# ADUC7023 register map
File version: 1.0
Registers are 32-bit, read-write, reset 0x0 unless marked. A register's access mark holds for its fields unless they carry their own. Offsets are from the block's base; lines under a group give offsets from that group; [hi:lo] are bit positions; {n}, {i} and the like mark numbered series; 'fields as' and 'values as' point back to an identical list; <NAME> marks a mode.

## Memory map
0xFFFF0000 IRQ size 0x140 — NTERRUPT CONTROLLER
0xFFFF0220 RSC size 0x18 — REMAP AND SYSTEM CONTROL
0xFFFF0300 TIMER0 size 0x10
0xFFFF0320 GPT size 0x14 — GENERAL-PURPOSE TIMER
0xFFFF0360 WDT size 0x10 — WATCHDOG TIMER
0xFFFF0404 PLL size 0x1C — PLL AND OSCILLATOR CONTROL
0xFFFF0440 PSM size 0x8 — POWER SUPPLY MONITOR
0xFFFF048C REF size 0x4 — BAND GAP REFERENCE
0xFFFF0500 ADC size 0x5C — Analog-to-Digital Converter
0xFFFF0600 DAC size 0x6C — Digital-to-Analog Converter
0xFFFF0800 I2C0 size 0x48 — I2C0 peripheral interfaces
0xFFFF0900 I2C1 size 0x48 — I2C1 peripheral interfaces
0xFFFF0A00 SPI size 0x14 — SERIAL PERIPHERAL INTERFACE
0xFFFF0B00 PLA size 0x54 — PROGRAMMABLE LOGIC ARRAY
0xFFFF0F80 PWM size 0x3F — PROGRAMMABLE LOGIC ARRAY
0xFFFFF400 GPIO size 0x50 — GENERAL-PURPOSE INPUT/OUTPUT
0xFFFFF800 FLASH size 0x20 — FLASH/EE CONTROL INTERFACE

## IRQ — NTERRUPT CONTROLLER
Base 0xFFFF0000
0x00 IRQSTA ro — Active IRQ source register
0x04 IRQSIG ro — Current state of all IRQ sources register
0x08 IRQEN — Enabled IRQ sources register
0x0C IRQCLR wo — Register to disable IRQ sources
0x10 SWICFG wo — Software interrupt configuration register
0x14 IRQBASE — Base address of all vectors register
0x1C IRQVEC ro — Currently active IRQ source register
{0x20+4i} IRQP{i} (i=0..2) — Interrupt priority setting register
0x30 IRQCONN — IRQ and FIQ interrupt nesting register
0x34 IRQCONE — External interrupt sources register
0x38 IRQCLRE — Clear an edge level triggered interrupt source register
0x3C IRQSTAN — Register indicates the priority level of an interrupt
0x100 FIQSTA ro — Active FIQ source register
0x104 FIQSIG ro — Current state of all FIQ sources register
0x108 FIQEN — Enabled FIQ sources register
0x10C FIQCLR wo — Register to disable FIQ sources
0x11C FIQVEC ro — FIQ interrupt vector register
0x13C FIQSTAN — Register indicates the priority level of an FIQ

## PSM — POWER SUPPLY MONITOR
Base 0xFFFF0440
0x00 PSMCON 16-bit reset 0x8 — Power supply monitor control register
0x04 CMPCON 16-bit — Comparator control register

## REF — BAND GAP REFERENCE
Base 0xFFFF048C
0x00 REFCON 8-bit — Band gap reference control register
  [0] REFOUT — Internal reference output enable bit

## ADC — Analog-to-Digital Converter
Base 0xFFFF0500
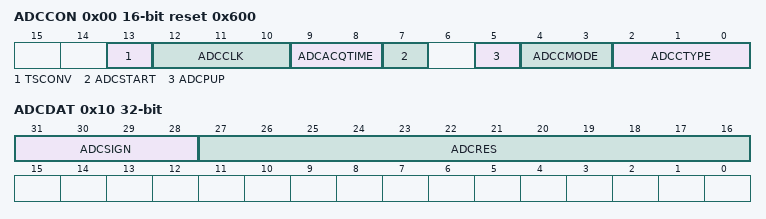
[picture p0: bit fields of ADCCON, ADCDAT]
0x00 ADCCON 16-bit reset 0x600 — ADC control register
  [13] TSCONV — Temperature sensor conversion enable bit
  [12:10] ADCCLK — ADC clock speed bits
  [9:8] ADCACQTIME — ADC acquisition time bits
  [7] ADCSTART — ADC Start bit
  [5] ADCPUP — ADC Power Up bit
  [4:3] ADCCMODE — ADC Conversion mode bits
  [2:0] ADCCTYPE — ADC Conversion type bits
0x04 ADCCP 8-bit — ADC positive channel selection register
  [4:0] ADCSEL — Positive channel selection bits
0x08 ADCCN 8-bit reset 0x1 — ADC negative channel selection register
  [4:0] ADCSEL — Negative channel selection bits
0x0C ADCSTA 8-bit ro — ADC status register
  [0] ADCREADY — ADC conversion result is ready bit
0x10 ADCDAT ro — ADC data result register
  [31:28] ADCSIGN — ADC data sign bits
  [27:16] ADCRES — ADC data result bits
0x14 ADCRST 8-bit — Resets the digital interface of the ADC
0x30 ADCGN 16-bit — ADC gain calibration register
0x34 ADCOF 16-bit — ADC offset calibration register
0x44 TSCON 8-bit — Temperature sensor chopping enable register
  [0] TSEN — Temperature sensor chop enable bit
0x48 TEMPREF 16-bit — Temperature sensor reference value

## DAC — Digital-to-Analog Converter
Base 0xFFFF0600
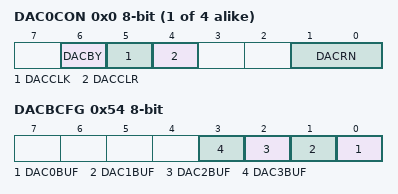
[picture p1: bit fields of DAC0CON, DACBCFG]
{0x0+8i} DAC{i}CON 8-bit (i=0..3) — DAC{i} control register
  [6] DACBY — DAC bypass the output buffer bit
  [5] DACCLK — DAC update rate
  [4] DACCLR — DAC clear bit
  [1:0] DACRN — DAC range bits
{0x4+8i} DAC{i}DAT (i=0..3) — DAC{i} data register
  [27:16] DACDAT — 12-bit data for DAC
0x50 DACBKEY0 16-bit wo — DAC Key0 register
0x54 DACBCFG 8-bit — DAC Configuration register
  [n] DAC{n}BUF (n=0..3) — DAC{n} output buffer in op amp mode bit
0x58 DACBKEY1 16-bit wo — DAC Key1 register
